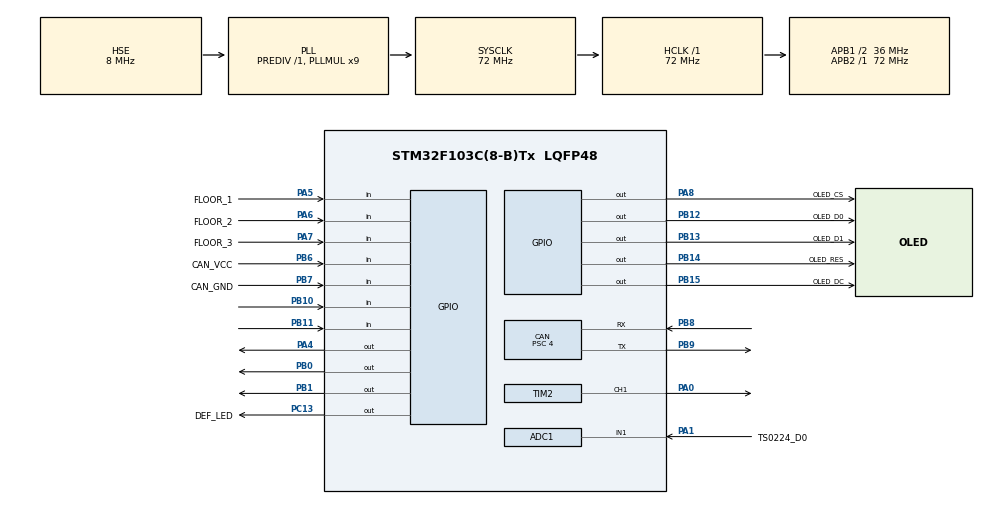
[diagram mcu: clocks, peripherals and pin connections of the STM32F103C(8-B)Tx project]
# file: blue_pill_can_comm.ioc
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ADC1.Channel-0\#ChannelRegularConversion=ADC_CHANNEL_1
ADC1.NbrOfConversionFlag=1
ADC1.Rank-0\#ChannelRegularConversion=1
ADC1.SamplingTime-0\#ChannelRegularConversion=ADC_SAMPLETIME_1CYCLE_5
ADC1.master=1
CAN.BS1=CAN_BS1_15TQ
CAN.BS2=CAN_BS2_2TQ
CAN.CalculateBaudRate=500000
CAN.CalculateTimeBit=2000
CAN.CalculateTimeQuantum=111.11111111111111
CAN.Prescaler=4
FREERTOS.Tasks01=defaultTask,24,256,StartDefaultTask,As weak,NULL,Dynamic,NULL,NULL;hallTask,8,128,HallTask,As weak,NULL,Dynamic,NULL,NULL
Mcu.Family=STM32F1
Mcu.Name=STM32F103C(8-B)Tx
Mcu.Package=LQFP48
NVIC.ADC1_2_IRQn=true\:5\:0\:false\:false\:true\:true\:true\:true\:true
NVIC.PriorityGroup=NVIC_PRIORITYGROUP_4
NVIC.USB_LP_CAN1_RX0_IRQn=true\:5\:0\:false\:false\:true\:true\:true\:true\:true
PA0-WKUP.Signal=S_TIM2_CH1_ETR
PA1.GPIO_Label=TS0224_D0
PA1.Signal=ADCx_IN1
PA13.Mode=Serial_Wire
PA13.Signal=SYS_JTMS-SWDIO
PA14.Mode=Serial_Wire
PA14.Signal=SYS_JTCK-SWCLK
PA4.GPIO_Speed=GPIO_SPEED_FREQ_HIGH
PA4.Signal=GPIO_Output
PA5.GPIO_Label=FLOOR_1
PA5.GPIO_PuPd=GPIO_PULLUP
PA5.Signal=GPIO_Input
PA6.GPIO_Label=FLOOR_2
PA6.GPIO_PuPd=GPIO_PULLUP
PA6.Signal=GPIO_Input
PA7.GPIO_Label=FLOOR_3
PA7.GPIO_PuPd=GPIO_PULLUP
PA7.Signal=GPIO_Input
PA8.GPIO_Label=OLED_CS
PA8.GPIO_Speed=GPIO_SPEED_FREQ_HIGH
PA8.Signal=GPIO_Output
PB0.GPIO_Speed=GPIO_SPEED_FREQ_HIGH
PB0.Signal=GPIO_Output
PB1.GPIO_Speed=GPIO_SPEED_FREQ_HIGH
PB1.Signal=GPIO_Output
PB10.GPIO_PuPd=GPIO_PULLUP
PB10.Signal=GPIO_Input
PB11.GPIO_PuPd=GPIO_PULLUP
PB11.Signal=GPIO_Input
PB12.GPIO_Label=OLED_D0
PB12.GPIO_Speed=GPIO_SPEED_FREQ_HIGH
PB12.Signal=GPIO_Output
PB13.GPIO_Label=OLED_D1
PB13.GPIO_Speed=GPIO_SPEED_FREQ_HIGH
PB13.Signal=GPIO_Output
PB14.GPIO_Label=OLED_RES
PB14.GPIO_Speed=GPIO_SPEED_FREQ_HIGH
PB14.Signal=GPIO_Output
PB15.GPIO_Label=OLED_DC
PB15.GPIO_Speed=GPIO_SPEED_FREQ_HIGH
PB15.Signal=GPIO_Output
PB6.GPIO_Label=CAN_VCC
PB6.Signal=GPIO_Input
PB7.GPIO_Label=CAN_GND
PB7.Signal=GPIO_Input
PB8.Mode=CAN_Activate
PB8.Signal=CAN_RX
PB9.Mode=CAN_Activate
PB9.Signal=CAN_TX
PC13-TAMPER-RTC.GPIO_Label=DEF_LED
PC13-TAMPER-RTC.Signal=GPIO_Output
PD0-OSC_IN.Mode=HSE-External-Oscillator
PD0-OSC_IN.Signal=RCC_OSC_IN
PD1-OSC_OUT.Mode=HSE-External-Oscillator
PD1-OSC_OUT.Signal=RCC_OSC_OUT
ProjectManager.HeapSize=0x200
ProjectManager.StackSize=0x400
ProjectManager.TargetToolchain=CMake
RCC.AHBFreq_Value=72000000
RCC.APB1CLKDivider=RCC_HCLK_DIV2
RCC.APB1Freq_Value=36000000
RCC.APB1TimFreq_Value=72000000
RCC.APB2Freq_Value=72000000
RCC.APB2TimFreq_Value=72000000
RCC.HCLKFreq_Value=72000000
RCC.PLLMUL=RCC_PLL_MUL9
RCC.PLLSourceVirtual=RCC_PLLSOURCE_HSE
RCC.SYSCLKFreq_VALUE=72000000
RCC.SYSCLKSource=RCC_SYSCLKSOURCE_PLLCLK
RCC.USBFreq_Value=72000000
SH.ADCx_IN1.0=ADC1_IN1,IN1
SH.S_TIM2_CH1_ETR.0=TIM2_CH1,PWM Generation1 CH1
TIM2.AutoReloadPreload=TIM_AUTORELOAD_PRELOAD_ENABLE
TIM2.Channel-PWM\ Generation1\ CH1=TIM_CHANNEL_1
TIM2.Period=19999
TIM2.Prescaler=71
VP_FREERTOS_VS_CMSIS_V2.Mode=CMSIS_V2
VP_TIM2_VS_ClockSourceINT.Mode=Internal
VP_TIM2_VS_ClockSourceITR.Mode=TriggerSource_ITR0
board=custom

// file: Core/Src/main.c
/* USER CODE BEGIN Header */
/**
  ******************************************************************************
  * @file           : main.c
  * @brief          : Main program body
  ******************************************************************************
  * @attention
  *
  * Copyright (c) 2026 STMicroelectronics.
  * All rights reserved.
  *
  * This software is licensed under terms that can be found in the LICENSE file
  * in the root directory of this software component.
  * If no LICENSE file comes with this software, it is provided AS-IS.
  *
  ******************************************************************************
  */
/* USER CODE END Header */
#include "main.h"
#include "cmsis_os.h"
#include "adc.h"
#include "can.h"
#include "tim.h"
#include "gpio.h"

void SystemClock_Config(void);
void MX_FREERTOS_Init(void);

int main(void)
{

  /* MCU Configuration--------------------------------------------------------*/

  /* Reset of all peripherals, Initializes the Flash interface and the Systick. */
  HAL_Init();

  /* Configure the system clock */
  SystemClock_Config();

  /* Initialize all configured peripherals */
  MX_GPIO_Init();
  MX_CAN_Init();
  MX_TIM2_Init();
  MX_ADC1_Init();
  /* USER CODE BEGIN 2 */
  //uart_init();

  /* USER CODE END 2 */

  /* Init scheduler */
  osKernelInitialize();  /* Call init function for freertos objects (in cmsis_os2.c) */
  MX_FREERTOS_Init();

  /* Start scheduler */
  osKernelStart();

  /* We should never get here as control is now taken by the scheduler */

  /* Infinite loop */
  while (1)
  {

  }
}

void SystemClock_Config(void)
{
  RCC_OscInitTypeDef RCC_OscInitStruct = {0};
  RCC_ClkInitTypeDef RCC_ClkInitStruct = {0};
  RCC_PeriphCLKInitTypeDef PeriphClkInit = {0};

  /** Initializes the RCC Oscillators according to the specified parameters
  * in the RCC_OscInitTypeDef structure.
  */
  RCC_OscInitStruct.OscillatorType = RCC_OSCILLATORTYPE_HSE;
  RCC_OscInitStruct.HSEState = RCC_HSE_ON;
  RCC_OscInitStruct.HSEPredivValue = RCC_HSE_PREDIV_DIV1;
  RCC_OscInitStruct.HSIState = RCC_HSI_ON;
  RCC_OscInitStruct.PLL.PLLState = RCC_PLL_ON;
  RCC_OscInitStruct.PLL.PLLSource = RCC_PLLSOURCE_HSE;
  RCC_OscInitStruct.PLL.PLLMUL = RCC_PLL_MUL9;
  if (HAL_RCC_OscConfig(&RCC_OscInitStruct) != HAL_OK)
  {
    Error_Handler();
  }

  /** Initializes the CPU, AHB and APB buses clocks
  */
  RCC_ClkInitStruct.ClockType = RCC_CLOCKTYPE_HCLK|RCC_CLOCKTYPE_SYSCLK
                              |RCC_CLOCKTYPE_PCLK1|RCC_CLOCKTYPE_PCLK2;
  RCC_ClkInitStruct.SYSCLKSource = RCC_SYSCLKSOURCE_PLLCLK;
  RCC_ClkInitStruct.AHBCLKDivider = RCC_SYSCLK_DIV1;
  RCC_ClkInitStruct.APB1CLKDivider = RCC_HCLK_DIV2;
  RCC_ClkInitStruct.APB2CLKDivider = RCC_HCLK_DIV1;

  if (HAL_RCC_ClockConfig(&RCC_ClkInitStruct, FLASH_LATENCY_2) != HAL_OK)
  {
    Error_Handler();
  }
  PeriphClkInit.PeriphClockSelection = RCC_PERIPHCLK_ADC;
  PeriphClkInit.AdcClockSelection = RCC_ADCPCLK2_DIV2;
  if (HAL_RCCEx_PeriphCLKConfig(&PeriphClkInit) != HAL_OK)
  {
    Error_Handler();
  }
}

void Error_Handler(void)
{
  __disable_irq();
  while (1)
  {
  }
}

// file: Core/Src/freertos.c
/* USER CODE BEGIN Header */
/**
  ******************************************************************************
  * File Name          : freertos.c
  * Description        : Code for freertos applications
  ******************************************************************************
  * @attention
  *
  * Copyright (c) 2026 STMicroelectronics.
  * All rights reserved.
  *
  * This software is licensed under terms that can be found in the LICENSE file
  * in the root directory of this software component.
  * If no LICENSE file comes with this software, it is provided AS-IS.
  *
  ******************************************************************************
  */
/* USER CODE END Header */

#include "FreeRTOS.h"
#include "task.h"
#include "main.h"
#include "cmsis_os.h"

/* Definitions for defaultTask */
osThreadId_t defaultTaskHandle;
const osThreadAttr_t defaultTask_attributes = {
  .name = "defaultTask",
  .stack_size = 256 * 4,
  .priority = (osPriority_t) osPriorityNormal,
};
/* Definitions for hallTask */
osThreadId_t hallTaskHandle;
const osThreadAttr_t hallTask_attributes = {
  .name = "hallTask",
  .stack_size = 128 * 4,
  .priority = (osPriority_t) osPriorityLow,
};

void StartDefaultTask(void *argument);
void HallTask(void *argument);

void MX_FREERTOS_Init(void); /* (MISRA C 2004 rule 8.1) */

void MX_FREERTOS_Init(void) {

  /* Create the thread(s) */
  /* creation of defaultTask */
  defaultTaskHandle = osThreadNew(StartDefaultTask, NULL, &defaultTask_attributes);

  /* creation of hallTask */
  hallTaskHandle = osThreadNew(HallTask, NULL, &hallTask_attributes);

}

__weak void StartDefaultTask(void *argument)
{
  for(;;)
  {
    osDelay(1);
  }
}

__weak void HallTask(void *argument)
{
  for(;;)
  {
    osDelay(1);
  }
}
